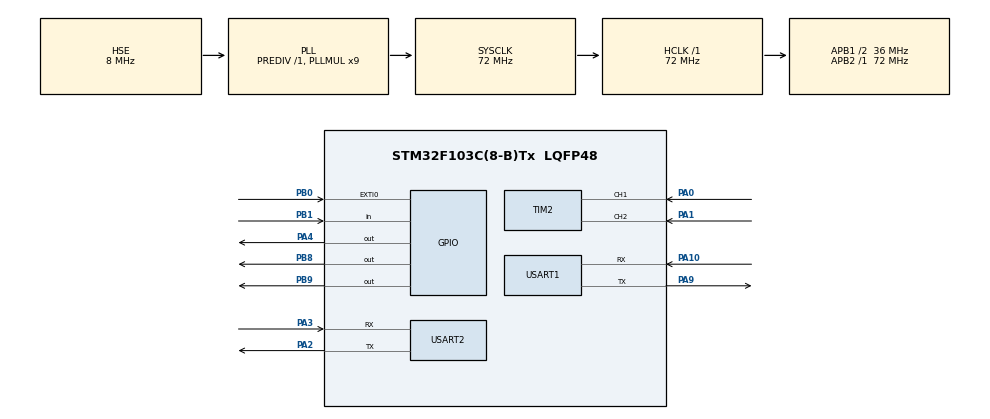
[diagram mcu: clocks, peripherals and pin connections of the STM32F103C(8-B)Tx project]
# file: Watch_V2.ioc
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Dma.Request0=USART1_RX
Dma.Request1=USART2_RX
Dma.USART1_RX.0.Direction=DMA_PERIPH_TO_MEMORY
Dma.USART1_RX.0.Instance=DMA1_Channel5
Dma.USART1_RX.0.MemDataAlignment=DMA_MDATAALIGN_BYTE
Dma.USART1_RX.0.MemInc=DMA_MINC_ENABLE
Dma.USART1_RX.0.Mode=DMA_CIRCULAR
Dma.USART1_RX.0.PeriphDataAlignment=DMA_PDATAALIGN_BYTE
Dma.USART1_RX.0.PeriphInc=DMA_PINC_DISABLE
Dma.USART1_RX.0.Priority=DMA_PRIORITY_LOW
Dma.USART2_RX.1.Direction=DMA_PERIPH_TO_MEMORY
Dma.USART2_RX.1.Instance=DMA1_Channel6
Dma.USART2_RX.1.MemDataAlignment=DMA_MDATAALIGN_BYTE
Dma.USART2_RX.1.MemInc=DMA_MINC_ENABLE
Dma.USART2_RX.1.Mode=DMA_CIRCULAR
Dma.USART2_RX.1.PeriphDataAlignment=DMA_PDATAALIGN_BYTE
Dma.USART2_RX.1.PeriphInc=DMA_PINC_DISABLE
Dma.USART2_RX.1.Priority=DMA_PRIORITY_LOW
FREERTOS.Tasks01=uiTask,0,256,StartDefaultTask,Default,NULL,Dynamic,NULL,NULL;netTas,-2,128,StartTask02,Default,NULL,Dynamic,NULL,NULL
FREERTOS.configTOTAL_HEAP_SIZE=5120
Mcu.Family=STM32F1
Mcu.Name=STM32F103C(8-B)Tx
Mcu.Package=LQFP48
NVIC.DMA1_Channel5_IRQn=true\:5\:0\:false\:false\:true\:true\:false\:true\:true
NVIC.DMA1_Channel6_IRQn=true\:5\:0\:false\:false\:true\:true\:false\:true\:true
NVIC.EXTI0_IRQn=true\:5\:0\:false\:false\:true\:true\:true\:true\:true
NVIC.PriorityGroup=NVIC_PRIORITYGROUP_4
NVIC.TIM4_IRQn=true\:0\:0\:true\:false\:true\:false\:false\:true\:true
NVIC.TimeBase=TIM4_IRQn
NVIC.TimeBaseIP=TIM4
NVIC.USART1_IRQn=true\:5\:0\:false\:false\:true\:true\:true\:true\:true
NVIC.USART2_IRQn=true\:5\:0\:false\:false\:true\:true\:true\:true\:true
PA0-WKUP.Signal=S_TIM2_CH1_ETR
PA1.Signal=S_TIM2_CH2
PA10.Mode=Asynchronous
PA10.Signal=USART1_RX
PA13.Mode=Serial_Wire
PA13.Signal=SYS_JTMS-SWDIO
PA14.Mode=Serial_Wire
PA14.Signal=SYS_JTCK-SWCLK
PA2.Mode=Asynchronous
PA2.Signal=USART2_TX
PA3.Mode=Asynchronous
PA3.Signal=USART2_RX
PA4.PinState=GPIO_PIN_SET
PA4.Signal=GPIO_Output
PA9.Mode=Asynchronous
PA9.Signal=USART1_TX
PB0.GPIO_ModeDefaultEXTI=GPIO_MODE_IT_FALLING
PB0.GPIO_PuPd=GPIO_PULLUP
PB0.Signal=GPXTI0
PB1.Signal=GPIO_Input
PB8.Signal=GPIO_Output
PB9.Signal=GPIO_Output
PD0-OSC_IN.Mode=HSE-External-Oscillator
PD0-OSC_IN.Signal=RCC_OSC_IN
PD1-OSC_OUT.Mode=HSE-External-Oscillator
PD1-OSC_OUT.Signal=RCC_OSC_OUT
ProjectManager.HeapSize=0x000
ProjectManager.StackSize=0x200
ProjectManager.TargetToolchain=MDK-ARM V5.32
RCC.AHBFreq_Value=72000000
RCC.APB1CLKDivider=RCC_HCLK_DIV2
RCC.APB1Freq_Value=36000000
RCC.APB1TimFreq_Value=72000000
RCC.APB2Freq_Value=72000000
RCC.APB2TimFreq_Value=72000000
RCC.HCLKFreq_Value=72000000
RCC.PLLMUL=RCC_PLL_MUL9
RCC.PLLSourceVirtual=RCC_PLLSOURCE_HSE
RCC.SYSCLKFreq_VALUE=72000000
RCC.SYSCLKSource=RCC_SYSCLKSOURCE_PLLCLK
RCC.USBFreq_Value=72000000
SH.S_TIM2_CH1_ETR.0=TIM2_CH1,Encoder_Interface
SH.S_TIM2_CH2.0=TIM2_CH2,Encoder_Interface
TIM2.EncoderMode=TIM_ENCODERMODE_TI12
TIM2.IC1Filter=8
TIM2.IC2Filter=8
USART1.VirtualMode=VM_ASYNC
USART2.VirtualMode=VM_ASYNC
VP_FREERTOS_VS_CMSIS_V1.Mode=CMSIS_V1
VP_SYS_VS_tim4.Mode=TIM4
board=custom

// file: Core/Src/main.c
/* USER CODE BEGIN Header */
/**
  ******************************************************************************
  * @file           : main.c
  * @brief          : Main program body
  ******************************************************************************
  * @attention
  *
  * Copyright (c) 2026 STMicroelectronics.
  * All rights reserved.
  *
  * This software is licensed under terms that can be found in the LICENSE file
  * in the root directory of this software component.
  * If no LICENSE file comes with this software, it is provided AS-IS.
  *
  ******************************************************************************
  */
/* USER CODE END Header */
#include "main.h"
#include "cmsis_os.h"
#include "dma.h"
#include "tim.h"
#include "usart.h"
#include "gpio.h"

void SystemClock_Config(void);
void MX_FREERTOS_Init(void);

int main(void)
{

  /* MCU Configuration--------------------------------------------------------*/

  /* Reset of all peripherals, Initializes the Flash interface and the Systick. */
  HAL_Init();

  /* Configure the system clock */
  SystemClock_Config();

  /* Initialize all configured peripherals */
  MX_GPIO_Init();
  MX_DMA_Init();
  MX_TIM2_Init();
  MX_USART1_UART_Init();
  MX_USART2_UART_Init();

  /* Call init function for freertos objects (in cmsis_os2.c) */
  MX_FREERTOS_Init();

  /* Start scheduler */
  osKernelStart();

  /* We should never get here as control is now taken by the scheduler */

  /* Infinite loop */
  while (1)
  {

  }
}

void SystemClock_Config(void)
{
  RCC_OscInitTypeDef RCC_OscInitStruct = {0};
  RCC_ClkInitTypeDef RCC_ClkInitStruct = {0};

  /** Initializes the RCC Oscillators according to the specified parameters
  * in the RCC_OscInitTypeDef structure.
  */
  RCC_OscInitStruct.OscillatorType = RCC_OSCILLATORTYPE_HSE;
  RCC_OscInitStruct.HSEState = RCC_HSE_ON;
  RCC_OscInitStruct.HSEPredivValue = RCC_HSE_PREDIV_DIV1;
  RCC_OscInitStruct.HSIState = RCC_HSI_ON;
  RCC_OscInitStruct.PLL.PLLState = RCC_PLL_ON;
  RCC_OscInitStruct.PLL.PLLSource = RCC_PLLSOURCE_HSE;
  RCC_OscInitStruct.PLL.PLLMUL = RCC_PLL_MUL9;
  if (HAL_RCC_OscConfig(&RCC_OscInitStruct) != HAL_OK)
  {
    Error_Handler();
  }

  /** Initializes the CPU, AHB and APB buses clocks
  */
  RCC_ClkInitStruct.ClockType = RCC_CLOCKTYPE_HCLK|RCC_CLOCKTYPE_SYSCLK
                              |RCC_CLOCKTYPE_PCLK1|RCC_CLOCKTYPE_PCLK2;
  RCC_ClkInitStruct.SYSCLKSource = RCC_SYSCLKSOURCE_PLLCLK;
  RCC_ClkInitStruct.AHBCLKDivider = RCC_SYSCLK_DIV1;
  RCC_ClkInitStruct.APB1CLKDivider = RCC_HCLK_DIV2;
  RCC_ClkInitStruct.APB2CLKDivider = RCC_HCLK_DIV1;

  if (HAL_RCC_ClockConfig(&RCC_ClkInitStruct, FLASH_LATENCY_2) != HAL_OK)
  {
    Error_Handler();
  }
}

void HAL_TIM_PeriodElapsedCallback(TIM_HandleTypeDef *htim)
{
  if (htim->Instance == TIM4)
  {
    HAL_IncTick();
  }
}

void Error_Handler(void)
{
  __disable_irq();
  while (1)
  {
  }
}

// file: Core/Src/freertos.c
/* USER CODE BEGIN Header */
/**
  ******************************************************************************
  * File Name          : freertos.c
  * Description        : Code for freertos applications
  ******************************************************************************
  * @attention
  *
  * Copyright (c) 2026 STMicroelectronics.
  * All rights reserved.
  *
  * This software is licensed under terms that can be found in the LICENSE file
  * in the root directory of this software component.
  * If no LICENSE file comes with this software, it is provided AS-IS.
  *
  ******************************************************************************
  */
/* USER CODE END Header */

#include "FreeRTOS.h"
#include "task.h"
#include "main.h"
#include "cmsis_os.h"

/* USER CODE BEGIN Includes */
#include "OLED.h"
#include "OLED_Data.h"
/* USER CODE END Includes */

osThreadId uiTaskHandle;
osThreadId netTasHandle;

void StartDefaultTask(void const * argument);
void StartTask02(void const * argument);

void MX_FREERTOS_Init(void); /* (MISRA C 2004 rule 8.1) */

/* GetIdleTaskMemory prototype (linked to static allocation support) */
void vApplicationGetIdleTaskMemory( StaticTask_t **ppxIdleTaskTCBBuffer, StackType_t **ppxIdleTaskStackBuffer, uint32_t *pulIdleTaskStackSize );

/* USER CODE BEGIN GET_IDLE_TASK_MEMORY */
static StaticTask_t xIdleTaskTCBBuffer;
static StackType_t xIdleStack[configMINIMAL_STACK_SIZE];

void vApplicationGetIdleTaskMemory( StaticTask_t **ppxIdleTaskTCBBuffer, StackType_t **ppxIdleTaskStackBuffer, uint32_t *pulIdleTaskStackSize )
{
  *ppxIdleTaskTCBBuffer = &xIdleTaskTCBBuffer;
  *ppxIdleTaskStackBuffer = &xIdleStack[0];
  *pulIdleTaskStackSize = configMINIMAL_STACK_SIZE;
  /* place for user code */
}
/* USER CODE END GET_IDLE_TASK_MEMORY */

void MX_FREERTOS_Init(void) {

  /* Create the thread(s) */
  /* definition and creation of uiTask */
  osThreadDef(uiTask, StartDefaultTask, osPriorityNormal, 0, 256);
  uiTaskHandle = osThreadCreate(osThread(uiTask), NULL);

  /* definition and creation of netTas */
  osThreadDef(netTas, StartTask02, osPriorityLow, 0, 128);
  netTasHandle = osThreadCreate(osThread(netTas), NULL);

}

void StartDefaultTask(void const * argument)
{
  /* USER CODE BEGIN StartDefaultTask */
  OLED_Init();

  OLED_Clear();

  OLED_ShowString(1,1,"HELLO",OLED_12X24);

  OLED_Update();

  /* Infinite loop */
  for(;;)
  {
    osDelay(500);
  }
  /* USER CODE END StartDefaultTask */
}

void StartTask02(void const * argument)
{
  for(;;)
  {
    osDelay(1);
  }
}
